# ATSAML22G16A register map
Vendor: Atmel Corporation; Series: SAML22; File version: A
CPU: CM0+ r0p1, little endian, MPU, no FPU, VTOR, 2 interrupt priority bits
Registers are 32-bit, read-write, reset 0x0 unless marked. A register's access mark holds for its fields unless they carry their own. Offsets are from the block's base; [hi:lo] are bit positions; {n}, {i} and the like mark numbered series; 'fields as' and 'values as' point back to an identical list.

## PM — Power Manager
Base 0x40000400; register names take the prefix PM_
0x00 CTRLA 8-bit — Control A
  [2] IORET — I/O Retention
0x01 SLEEPCFG 8-bit reset 0x2 — Sleep Configuration
  [2:0] SLEEPMODE
    0=IDLE0 (CPU clock is OFF); 1=IDLE1 (AHB clock is OFF); 2=IDLE2 (APB clock are OFF); 4=STANDBY (All Clocks are OFF); 5=BACKUP (Only Backup domain is powered ON); 6=OFF (All power domains are powered OFF)
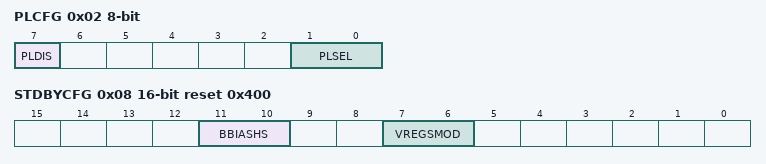
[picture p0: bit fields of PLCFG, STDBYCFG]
0x02 PLCFG 8-bit — Performance Level Configuration
  [7] PLDIS — Performance Level Disable
  [1:0] PLSEL — Performance Level Select
    0=PL0 (Performance Level 0); 1=PL1 (Performance Level 1); 2=PL2 (Performance Level 2)
0x04 INTENCLR 8-bit — Interrupt Enable Clear
  [0] PLRDY wo — Performance Level Interrupt Enable
0x05 INTENSET 8-bit — Interrupt Enable Set
  [0] PLRDY — Performance Level Ready interrupt Enable
0x06 INTFLAG 8-bit — Interrupt Flag Status and Clear
  [0] PLRDY — Performance Level Ready
0x08 STDBYCFG 16-bit reset 0x400 — Standby Configuration
  [11:10] BBIASHS — Back Bias for HMCRAMCHS
  [7:6] VREGSMOD — Voltage Regulator Standby mode
    0=AUTO (Automatic mode); 1=PERFORMANCE (Performance oriented); 2=LP (Low Power oriented)

## PORT — Port Module
Base 0x41006000; register names take the prefix PORT_
{0x0+0x80*i} DIR{i} (i=0..1) — Data Direction
{0x4+0x80*i} DIRCLR{i} (i=0..1) — Data Direction Clear
{0x8+0x80*i} DIRSET{i} (i=0..1) — Data Direction Set
{0xC+0x80*i} DIRTGL{i} (i=0..1) — Data Direction Toggle
{0x10+0x80*i} OUT{i} (i=0..1) — Data Output Value
{0x14+0x80*i} OUTCLR{i} (i=0..1) — Data Output Value Clear
{0x18+0x80*i} OUTSET{i} (i=0..1) — Data Output Value Set
{0x1C+0x80*i} OUTTGL{i} (i=0..1) — Data Output Value Toggle
{0x20+0x80*i} IN{i} (i=0..1) ro — Data Input Value
{0x24+0x80*i} CTRL{i} (i=0..1) — Control
  [31:0] SAMPLING wo — Input Sampling Mode
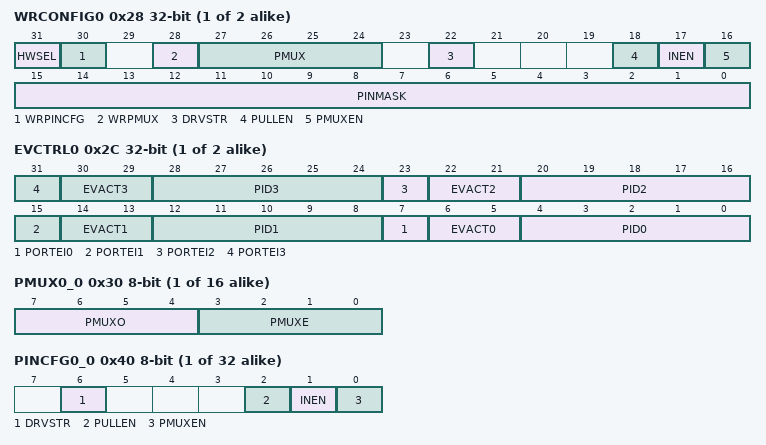
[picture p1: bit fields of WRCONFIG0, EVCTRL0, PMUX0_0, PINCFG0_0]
{0x28+0x80*i} WRCONFIG{i} (i=0..1) wo — Write Configuration
  [31] HWSEL — Half-Word Select
  [30] WRPINCFG — Write PINCFG Registers
  [28] WRPMUX — Write PMUX Registers
  [27:24] PMUX — Peripheral Multiplexing Template
  [22] DRVSTR — Output Driver Strength Selection
  [18] PULLEN — Pull Enable
  [17] INEN — Input Enable
  [16] PMUXEN — Select Peripheral Multiplexer
  [15:0] PINMASK — Pin Mask for Multiple Pin Configuration
{0x2C+0x80*i} EVCTRL{i} (i=0..1) — Event Input Control
  [8n+7] PORTEI{n} (n=0..3) — Port Event Enable Input {n}
  [8n+6:8n+5] EVACT{n} (n=0..3) — Port Event Action {n}
  [8n+4:8n] PID{n} (n=0..3) — Port Event Pin Identifier {n}
{0x30+i} PMUX0_{i} (i=0..15) 8-bit — Peripheral Multiplexing n - Group 0
  [7:4] PMUXO — Peripheral Multiplexing for Odd-Numbered Pin
  [3:0] PMUXE — Peripheral Multiplexing for Even-Numbered Pin
{0x40+i} PINCFG0_{i} (i=0..31) 8-bit — Pin Configuration n - Group 0
  [6] DRVSTR wo — Output Driver Strength Selection
  [2] PULLEN — Pull Enable
  [1] INEN — Input Enable
  [0] PMUXEN — Select Peripheral Multiplexer
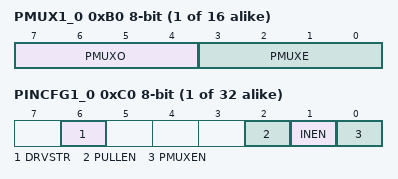
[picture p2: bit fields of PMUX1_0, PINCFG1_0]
{0xB0+i} PMUX1_{i} (i=0..15) 8-bit — Peripheral Multiplexing n - Group 1
  fields as PMUX0_0
{0xC0+i} PINCFG1_{i} (i=0..31) 8-bit — Pin Configuration n - Group 1
  fields as PINCFG0_0

## RSTC — Reset Controller
Base 0x40000C00; register names take the prefix RSTC_
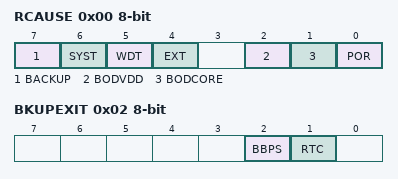
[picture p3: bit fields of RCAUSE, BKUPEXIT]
0x00 RCAUSE 8-bit ro — Reset Cause
  [7] BACKUP — Backup Reset
  [6] SYST — System Reset Request
  [5] WDT — Watchdog Reset
  [4] EXT — External Reset
  [2] BODVDD — Brown Out VDD Detector Reset
  [1] BODCORE — Brown Out CORE Detector Reset
  [0] POR — Power On Reset
0x02 BKUPEXIT 8-bit ro — Backup Exit Source
  [2] BBPS — Battery Backup Power Switch
  [1] RTC — Real Timer Counter Interrupt

## TAL — Trigger Allocator
Base 0x40003000; register names take the prefix TAL_
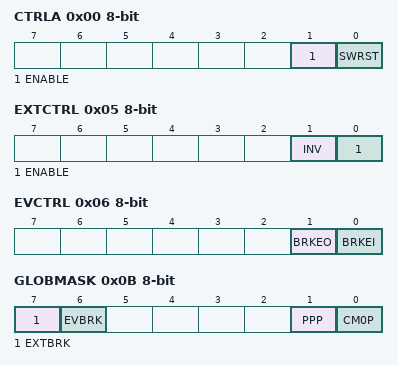
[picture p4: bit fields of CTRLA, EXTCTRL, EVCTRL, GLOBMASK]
0x00 CTRLA 8-bit — Control A
  [1] ENABLE
  [0] SWRST — Software Reset
0x04 RSTCTRL 8-bit — Reset Control
0x05 EXTCTRL 8-bit — External Break Control
  [1] INV — Invert BRK Pin
  [0] ENABLE — Enable BRK Pin
0x06 EVCTRL 8-bit — Event Control
  [1] BRKEO — Break Output Event Enable
  [0] BRKEI — Break Input Event Enable
0x08 INTENCLR 8-bit — Interrupt Enable Clear
  [0] BRK — Break Interrupt Enable
0x09 INTENSET 8-bit — Interrupt Enable Set
  [0] BRK — Break Interrupt Enable
0x0A INTFLAG 8-bit — Interrupt Flag Status and Clear
  [0] BRK — Break
0x0B GLOBMASK 8-bit — Global Break Requests Mask
  [7] EXTBRK — External Break Master
  [6] EVBRK — Event Break Master
  [1] PPP — PPP Break Master
  [0] CM0P — CM0P Break Master
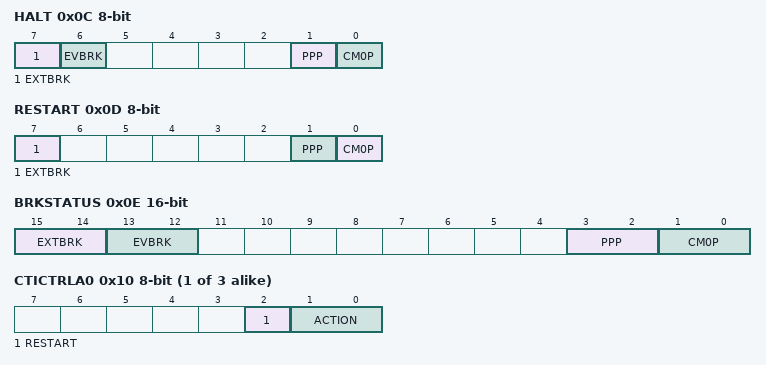
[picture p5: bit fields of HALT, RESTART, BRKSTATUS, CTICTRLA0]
0x0C HALT 8-bit wo — Debug Halt Request
  fields as GLOBMASK
0x0D RESTART 8-bit wo — Debug Restart Request
  [7] EXTBRK — External Break Master
  [1] PPP — PPP Break Master
  [0] CM0P — CM0P Break Master
0x0E BRKSTATUS 16-bit ro — Break Request Status
  [15:14] EXTBRK — External Break Request
  [13:12] EVBRK — Event Break Request
  [3:2] PPP — PPP Break Request
  [1:0] CM0P — CM0P Break Request
{0x10+2i} CTICTRLA{i} (i=0..2) 8-bit — Cross-Trigger Interface n Control A
  [2] RESTART — Action when global restart issued
    0=RESTART (Restart when requested); 1=IGNORE (Ignore restart request)
  [1:0] ACTION — Action when global break issued
    0=BREAK (Break when requested); 1=INTERRUPT (Trigger DBG interrupt instead of break); 2=IGNORE (Ignore break request)
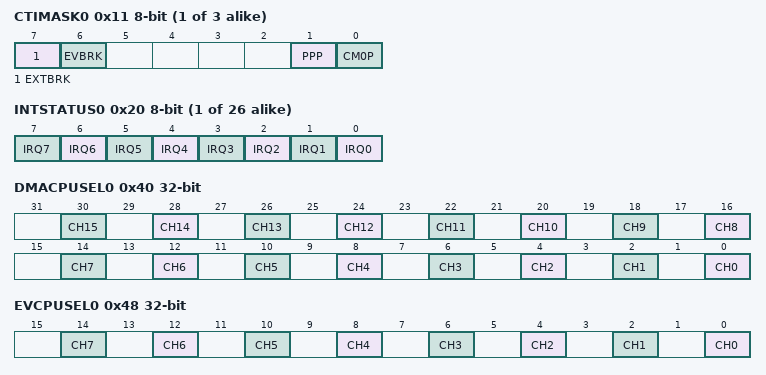
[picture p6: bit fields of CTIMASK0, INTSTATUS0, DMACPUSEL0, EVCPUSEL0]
{0x11+2i} CTIMASK{i} (i=0..2) 8-bit — Cross-Trigger Interface n Mask
  fields as GLOBMASK
{0x20+i} INTSTATUS{i} (i=0..25) 8-bit ro — Interrupt n Status
  [n] IRQ{n} (n=0..7) — Interrupt Status for Interrupt Request {n} within Interrupt n
0x40 DMACPUSEL0 — DMA Channel Interrupts CPU Select 0
  [2n] CH{n} (n=0..15) — DMA Channel {n} Interrupt CPU Select
0x48 EVCPUSEL0 — EVSYS Channel Interrupts CPU Select 0
  [2n] CH{n} (n=0..7) — Event Channel {n} Interrupt CPU Select
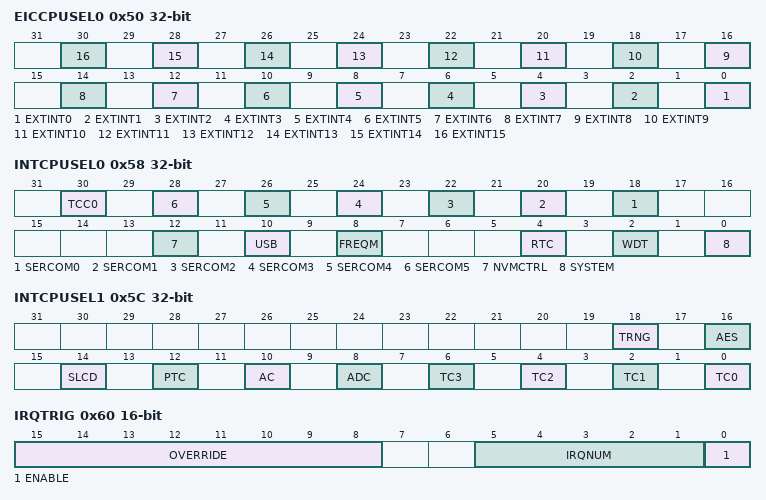
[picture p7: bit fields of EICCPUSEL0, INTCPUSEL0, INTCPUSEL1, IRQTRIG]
0x50 EICCPUSEL0 — EIC External Interrupts CPU Select 0
  [2n] EXTINT{n} (n=0..15) — External Interrupt {n} CPU Select
0x58 INTCPUSEL0 — Interrupts CPU Select 0
  [30] TCC0 — TCC0 Interrupt CPU Select
  [2n+18] SERCOM{n} (n=0..5) — SERCOM{n} Interrupt CPU Select
  [12] NVMCTRL — NVMCTRL Interrupt CPU Select
  [10] USB — USB Interrupt CPU Select
  [8] FREQM — FREQM Interrupt CPU Select
  [4] RTC — RTC Interrupt CPU Select
  [2] WDT — WDT Interrupt CPU Select
  [0] SYSTEM — SYSTEM Interrupt CPU Select
0x5C INTCPUSEL1 — Interrupts CPU Select 1
  [18] TRNG — TRNG Interrupt CPU Select
  [16] AES — AES Interrupt CPU Select
  [14] SLCD — SLCD Interrupt CPU Select
  [12] PTC — PTC Interrupt CPU Select
  [10] AC — AC Interrupt CPU Select
  [8] ADC — ADC Interrupt CPU Select
  [2n] TC{n} (n=0..3) — TC{n} Interrupt CPU Select
0x60 IRQTRIG 16-bit — Interrupt Trigger
  [15:8] OVERRIDE — Interrupt Request Override Value
  [5:1] IRQNUM — Interrupt Request Number
  [0] ENABLE — Trigger Enable
{0x64+4i} CPUIRQS{i} (i=0..0) ro — Interrupt Status for CPU n
  [25:0] CPUIRQS — Interrupt Requests for CPU n

## TRNG — True Random Generator
Base 0x42004400; register names take the prefix TRNG_
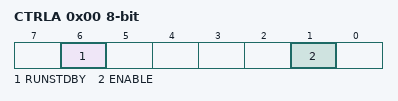
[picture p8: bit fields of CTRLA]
0x00 CTRLA 8-bit — Control A
  [6] RUNSTDBY — Run in Standby
  [1] ENABLE
0x04 EVCTRL 8-bit — Event Control
  [0] DATARDYEO — Data Ready Event Output
0x08 INTENCLR 8-bit — Interrupt Enable Clear
  [0] DATARDY — Data Ready Interrupt Enable
0x09 INTENSET 8-bit — Interrupt Enable Set
  [0] DATARDY — Data Ready Interrupt Enable
0x0A INTFLAG 8-bit — Interrupt Flag Status and Clear
  [0] DATARDY — Data Ready Interrupt Flag
0x20 DATA ro — Output Data

## WDT — Watchdog Timer
Base 0x40002000; register names take the prefix WDT_
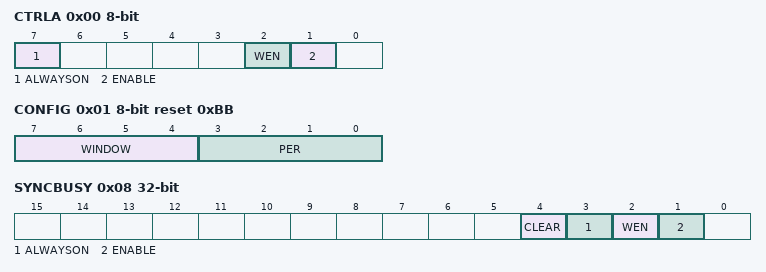
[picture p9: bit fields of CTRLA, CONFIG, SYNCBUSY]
0x00 CTRLA 8-bit — Control
  [7] ALWAYSON
  [2] WEN — Watchdog Timer Window Mode Enable
  [1] ENABLE
0x01 CONFIG 8-bit reset 0xBB — Configuration
  [7:4] WINDOW — Window Mode Time-Out Period
    0=CYC8 (8 clock cycles); 1=CYC16 (16 clock cycles); 2=CYC32 (32 clock cycles); 3=CYC64 (64 clock cycles); 4=CYC128 (128 clock cycles); 5=CYC256 (256 clock cycles); 6=CYC512 (512 clock cycles); 7=CYC1024 (1024 clock cycles); 8=CYC2048 (2048 clock cycles); 9=CYC4096 (4096 clock cycles); 10=CYC8192 (8192 clock cycles); 11=CYC16384 (16384 clock cycles)
  [3:0] PER — Time-Out Period
    values as WINDOW
0x02 EWCTRL 8-bit reset 0xB — Early Warning Interrupt Control
  [3:0] EWOFFSET — Early Warning Interrupt Time Offset
    values as CONFIG.WINDOW
0x04 INTENCLR 8-bit — Interrupt Enable Clear
  [0] EW — Early Warning Interrupt Enable
0x05 INTENSET 8-bit — Interrupt Enable Set
  [0] EW — Early Warning Interrupt Enable
0x06 INTFLAG 8-bit — Interrupt Flag Status and Clear
  [0] EW — Early Warning
0x08 SYNCBUSY ro — Synchronization Busy
  [4] CLEAR — Clear Busy
  [3] ALWAYSON — Always-On Busy
  [2] WEN — Window Enable Busy
  [1] ENABLE — Enable Busy
0x0C CLEAR 8-bit wo
  [7:0] CLEAR — Watchdog Clear
    165=KEY (Clear Key)
